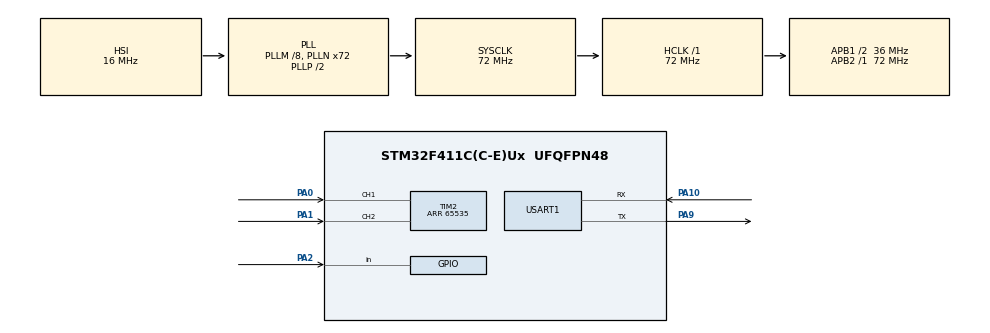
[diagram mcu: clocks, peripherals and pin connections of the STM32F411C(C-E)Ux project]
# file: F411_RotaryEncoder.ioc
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Mcu.Family=STM32F4
Mcu.Name=STM32F411C(C-E)Ux
Mcu.Package=UFQFPN48
NVIC.PriorityGroup=NVIC_PRIORITYGROUP_4
PA0-WKUP.Signal=S_TIM2_CH1_ETR
PA1.Signal=S_TIM2_CH2
PA10.Mode=Asynchronous
PA10.Signal=USART1_RX
PA2.GPIO_PuPd=GPIO_NOPULL
PA2.Signal=GPIO_Input
PA9.Mode=Asynchronous
PA9.Signal=USART1_TX
PH0\ -\ OSC_IN.Mode=HSE-External-Oscillator
PH0\ -\ OSC_IN.Signal=RCC_OSC_IN
PH1\ -\ OSC_OUT.Mode=HSE-External-Oscillator
PH1\ -\ OSC_OUT.Signal=RCC_OSC_OUT
ProjectManager.HeapSize=0x200
ProjectManager.StackSize=0x400
ProjectManager.TargetToolchain=STM32CubeIDE
RCC.48MHZClocksFreq_Value=36000000
RCC.AHBFreq_Value=72000000
RCC.APB1CLKDivider=RCC_HCLK_DIV2
RCC.APB1Freq_Value=36000000
RCC.APB1TimFreq_Value=72000000
RCC.APB2Freq_Value=72000000
RCC.APB2TimFreq_Value=72000000
RCC.CortexFreq_Value=72000000
RCC.HCLKFreq_Value=72000000
RCC.HSE_VALUE=25000000
RCC.HSI_VALUE=16000000
RCC.LSE_VALUE=32768
RCC.PLLM=8
RCC.PLLN=72
RCC.SYSCLKFreq_VALUE=72000000
RCC.SYSCLKSource=RCC_SYSCLKSOURCE_PLLCLK
RCC.VCOOutputFreq_Value=144000000
SH.S_TIM2_CH1_ETR.0=TIM2_CH1,Encoder_Interface
SH.S_TIM2_CH2.0=TIM2_CH2,Encoder_Interface
TIM2.AutoReloadPreload=TIM_AUTORELOAD_PRELOAD_ENABLE
TIM2.EncoderMode=TIM_ENCODERMODE_TI12
TIM2.IC1Filter=10
TIM2.IC2Filter=10
TIM2.Period=65535
USART1.VirtualMode=VM_ASYNC
board=custom

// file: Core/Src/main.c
/* USER CODE BEGIN Header */
/**
 ******************************************************************************
 * @file           : main.c
 * @brief          : Main program body
 ******************************************************************************
 * @attention
 *
 * Copyright (c) 2023 STMicroelectronics.
 * All rights reserved.
 *
 * This software is licensed under terms that can be found in the LICENSE file
 * in the root directory of this software component.
 * If no LICENSE file comes with this software, it is provided AS-IS.
 *
 ******************************************************************************
 */
/* USER CODE END Header */
#include "main.h"

/* USER CODE BEGIN Includes */
#include "stdio.h"
/* USER CODE END Includes */

TIM_HandleTypeDef htim2;

UART_HandleTypeDef huart1;

void SystemClock_Config(void);
static void MX_GPIO_Init(void);
static void MX_TIM2_Init(void);
static void MX_USART1_UART_Init(void);

int main(void)
{

  /* MCU Configuration--------------------------------------------------------*/

  /* Reset of all peripherals, Initializes the Flash interface and the Systick. */
  HAL_Init();

  /* Configure the system clock */
  SystemClock_Config();

  /* Initialize all configured peripherals */
  MX_GPIO_Init();
  MX_TIM2_Init();
  MX_USART1_UART_Init();
  /* USER CODE BEGIN 2 */
	HAL_TIM_Encoder_Start(&htim2, TIM_CHANNEL_ALL);
  /* USER CODE END 2 */

  /* Infinite loop */
  /* USER CODE BEGIN WHILE */
	while (1) {
		if (HAL_GPIO_ReadPin(GPIOA, GPIO_PIN_2)) {
			printf("Encoder Ticks: %ld | Released\r\n",((TIM2->CNT) >> 2));
		} else {
			printf("Encoder Ticks: %ld | Pressed\r\n",((TIM2->CNT) >> 2));
		}
		HAL_Delay(100);
    /* USER CODE END WHILE */

	}
}

void SystemClock_Config(void)
{
  RCC_OscInitTypeDef RCC_OscInitStruct = {0};
  RCC_ClkInitTypeDef RCC_ClkInitStruct = {0};

  /** Configure the main internal regulator output voltage
  */
  __HAL_RCC_PWR_CLK_ENABLE();
  __HAL_PWR_VOLTAGESCALING_CONFIG(PWR_REGULATOR_VOLTAGE_SCALE1);
  /** Initializes the RCC Oscillators according to the specified parameters
  * in the RCC_OscInitTypeDef structure.
  */
  RCC_OscInitStruct.OscillatorType = RCC_OSCILLATORTYPE_HSI;
  RCC_OscInitStruct.HSIState = RCC_HSI_ON;
  RCC_OscInitStruct.HSICalibrationValue = RCC_HSICALIBRATION_DEFAULT;
  RCC_OscInitStruct.PLL.PLLState = RCC_PLL_ON;
  RCC_OscInitStruct.PLL.PLLSource = RCC_PLLSOURCE_HSI;
  RCC_OscInitStruct.PLL.PLLM = 8;
  RCC_OscInitStruct.PLL.PLLN = 72;
  RCC_OscInitStruct.PLL.PLLP = RCC_PLLP_DIV2;
  RCC_OscInitStruct.PLL.PLLQ = 4;
  if (HAL_RCC_OscConfig(&RCC_OscInitStruct) != HAL_OK)
  {
    Error_Handler();
  }
  /** Initializes the CPU, AHB and APB buses clocks
  */
  RCC_ClkInitStruct.ClockType = RCC_CLOCKTYPE_HCLK|RCC_CLOCKTYPE_SYSCLK
                              |RCC_CLOCKTYPE_PCLK1|RCC_CLOCKTYPE_PCLK2;
  RCC_ClkInitStruct.SYSCLKSource = RCC_SYSCLKSOURCE_PLLCLK;
  RCC_ClkInitStruct.AHBCLKDivider = RCC_SYSCLK_DIV1;
  RCC_ClkInitStruct.APB1CLKDivider = RCC_HCLK_DIV2;
  RCC_ClkInitStruct.APB2CLKDivider = RCC_HCLK_DIV1;

  if (HAL_RCC_ClockConfig(&RCC_ClkInitStruct, FLASH_LATENCY_2) != HAL_OK)
  {
    Error_Handler();
  }
}

static void MX_TIM2_Init(void)
{

  TIM_Encoder_InitTypeDef sConfig = {0};
  TIM_MasterConfigTypeDef sMasterConfig = {0};

  htim2.Instance = TIM2;
  htim2.Init.Prescaler = 0;
  htim2.Init.CounterMode = TIM_COUNTERMODE_UP;
  htim2.Init.Period = 65535;
  htim2.Init.ClockDivision = TIM_CLOCKDIVISION_DIV1;
  htim2.Init.AutoReloadPreload = TIM_AUTORELOAD_PRELOAD_ENABLE;
  sConfig.EncoderMode = TIM_ENCODERMODE_TI12;
  sConfig.IC1Polarity = TIM_ICPOLARITY_RISING;
  sConfig.IC1Selection = TIM_ICSELECTION_DIRECTTI;
  sConfig.IC1Prescaler = TIM_ICPSC_DIV1;
  sConfig.IC1Filter = 10;
  sConfig.IC2Polarity = TIM_ICPOLARITY_RISING;
  sConfig.IC2Selection = TIM_ICSELECTION_DIRECTTI;
  sConfig.IC2Prescaler = TIM_ICPSC_DIV1;
  sConfig.IC2Filter = 10;
  if (HAL_TIM_Encoder_Init(&htim2, &sConfig) != HAL_OK)
  {
    Error_Handler();
  }
  sMasterConfig.MasterOutputTrigger = TIM_TRGO_RESET;
  sMasterConfig.MasterSlaveMode = TIM_MASTERSLAVEMODE_DISABLE;
  if (HAL_TIMEx_MasterConfigSynchronization(&htim2, &sMasterConfig) != HAL_OK)
  {
    Error_Handler();
  }

}

static void MX_USART1_UART_Init(void)
{

  huart1.Instance = USART1;
  huart1.Init.BaudRate = 115200;
  huart1.Init.WordLength = UART_WORDLENGTH_8B;
  huart1.Init.StopBits = UART_STOPBITS_1;
  huart1.Init.Parity = UART_PARITY_NONE;
  huart1.Init.Mode = UART_MODE_TX_RX;
  huart1.Init.HwFlowCtl = UART_HWCONTROL_NONE;
  huart1.Init.OverSampling = UART_OVERSAMPLING_16;
  if (HAL_UART_Init(&huart1) != HAL_OK)
  {
    Error_Handler();
  }

}

static void MX_GPIO_Init(void)
{
  GPIO_InitTypeDef GPIO_InitStruct = {0};

  /* GPIO Ports Clock Enable */
  __HAL_RCC_GPIOH_CLK_ENABLE();
  __HAL_RCC_GPIOA_CLK_ENABLE();

  /*Configure GPIO pin : PA2 */
  GPIO_InitStruct.Pin = GPIO_PIN_2;
  GPIO_InitStruct.Mode = GPIO_MODE_INPUT;
  GPIO_InitStruct.Pull = GPIO_NOPULL;
  HAL_GPIO_Init(GPIOA, &GPIO_InitStruct);

}

/* USER CODE BEGIN 4 */
int __io_putchar(int ch){
	HAL_UART_Transmit(&huart1,(uint8_t*)&ch,1,100);
	return 0;
}
/* USER CODE END 4 */

void Error_Handler(void)
{
	__disable_irq();
	while (1) {
	}
}
